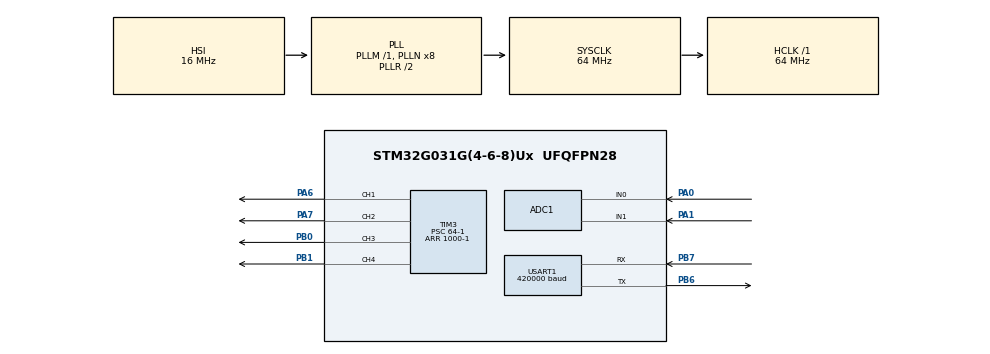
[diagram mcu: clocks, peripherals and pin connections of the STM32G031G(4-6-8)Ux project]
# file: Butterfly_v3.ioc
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ADC1.Channel-1\#ChannelRegularConversion=ADC_CHANNEL_0
ADC1.Channel-2\#ChannelRegularConversion=ADC_CHANNEL_1
ADC1.Channel-3\#ChannelRegularConversion=ADC_CHANNEL_TEMPSENSOR
ADC1.Channel-4\#ChannelRegularConversion=ADC_CHANNEL_VREFINT
ADC1.ContinuousConvMode=ENABLE
ADC1.NbrOfConversion=4
ADC1.NbrOfConversionFlag=1
ADC1.Rank-1\#ChannelRegularConversion=1
ADC1.Rank-2\#ChannelRegularConversion=2
ADC1.Rank-3\#ChannelRegularConversion=3
ADC1.Rank-4\#ChannelRegularConversion=4
ADC1.SamplingTime-1\#ChannelRegularConversion=ADC_SAMPLINGTIME_COMMON_1
ADC1.SamplingTime-2\#ChannelRegularConversion=ADC_SAMPLINGTIME_COMMON_1
ADC1.SamplingTime-3\#ChannelRegularConversion=ADC_SAMPLINGTIME_COMMON_1
ADC1.SamplingTime-4\#ChannelRegularConversion=ADC_SAMPLINGTIME_COMMON_1
ADC1.SamplingTimeCommon1=ADC_SAMPLETIME_160CYCLES_5
ADC1.SelectedChannel=ADC_CHANNEL_0|ADC_CHANNEL_1|ADC_CHANNEL_TEMPSENSOR|ADC_CHANNEL_VREFINT
ADC1.master=1
Dma.ADC1.1.Direction=DMA_PERIPH_TO_MEMORY
Dma.ADC1.1.EventEnable=DISABLE
Dma.ADC1.1.Instance=DMA1_Channel2
Dma.ADC1.1.MemDataAlignment=DMA_MDATAALIGN_HALFWORD
Dma.ADC1.1.MemInc=DMA_MINC_ENABLE
Dma.ADC1.1.Mode=DMA_CIRCULAR
Dma.ADC1.1.PeriphDataAlignment=DMA_PDATAALIGN_HALFWORD
Dma.ADC1.1.PeriphInc=DMA_PINC_DISABLE
Dma.ADC1.1.Polarity=HAL_DMAMUX_REQ_GEN_RISING
Dma.ADC1.1.Priority=DMA_PRIORITY_LOW
Dma.ADC1.1.RequestNumber=1
Dma.ADC1.1.SignalID=NONE
Dma.ADC1.1.SyncEnable=DISABLE
Dma.ADC1.1.SyncPolarity=HAL_DMAMUX_SYNC_NO_EVENT
Dma.ADC1.1.SyncRequestNumber=1
Dma.ADC1.1.SyncSignalID=NONE
Dma.Request0=USART1_RX
Dma.Request1=ADC1
Dma.USART1_RX.0.Direction=DMA_PERIPH_TO_MEMORY
Dma.USART1_RX.0.EventEnable=DISABLE
Dma.USART1_RX.0.Instance=DMA1_Channel1
Dma.USART1_RX.0.MemDataAlignment=DMA_MDATAALIGN_BYTE
Dma.USART1_RX.0.MemInc=DMA_MINC_ENABLE
Dma.USART1_RX.0.Mode=DMA_NORMAL
Dma.USART1_RX.0.PeriphDataAlignment=DMA_PDATAALIGN_BYTE
Dma.USART1_RX.0.PeriphInc=DMA_PINC_DISABLE
Dma.USART1_RX.0.Polarity=HAL_DMAMUX_REQ_GEN_RISING
Dma.USART1_RX.0.Priority=DMA_PRIORITY_LOW
Dma.USART1_RX.0.RequestNumber=1
Dma.USART1_RX.0.SignalID=NONE
Dma.USART1_RX.0.SyncEnable=DISABLE
Dma.USART1_RX.0.SyncPolarity=HAL_DMAMUX_SYNC_NO_EVENT
Dma.USART1_RX.0.SyncRequestNumber=1
Dma.USART1_RX.0.SyncSignalID=NONE
Mcu.Family=STM32G0
Mcu.Name=STM32G031G(4-6-8)Ux
Mcu.Package=UFQFPN28
NVIC.DMA1_Channel1_IRQn=true\:0\:0\:false\:false\:true\:false\:true\:true
NVIC.DMA1_Channel2_3_IRQn=true\:0\:0\:false\:false\:true\:false\:true\:true
NVIC.TIM17_IRQn=true\:3\:0\:false\:false\:true\:false\:true\:true
NVIC.TimeBase=TIM17_IRQn
NVIC.TimeBaseIP=TIM17
PA0.Mode=IN0
PA0.Signal=ADC1_IN0
PA1.Mode=IN1
PA1.Signal=ADC1_IN1
PA13.Mode=Serial_Wire
PA13.Signal=SYS_SWDIO
PA14-BOOT0.Mode=Serial_Wire
PA14-BOOT0.Signal=SYS_SWCLK
PA6.Signal=S_TIM3_CH1
PA7.Signal=S_TIM3_CH2
PB0.Signal=S_TIM3_CH3
PB1.Signal=S_TIM3_CH4
PB6.Mode=Asynchronous
PB6.Signal=USART1_TX
PB7.Mode=Asynchronous
PB7.Signal=USART1_RX
ProjectManager.HeapSize=0x200
ProjectManager.StackSize=0x400
ProjectManager.TargetToolchain=CMake
RCC.ADCFreq_Value=64000000
RCC.AHBFreq_Value=64000000
RCC.CortexFreq_Value=64000000
RCC.EXTERNAL_CLOCK_VALUE=12288000
RCC.HCLKFreq_Value=64000000
RCC.HSE_VALUE=8000000
RCC.HSI_VALUE=16000000
RCC.SYSCLKFreq_VALUE=64000000
RCC.SYSCLKSource=RCC_SYSCLKSOURCE_PLLCLK
RCC.VCOOutputFreq_Value=128000000
SH.S_TIM3_CH1.0=TIM3_CH1,PWM Generation1 CH1
SH.S_TIM3_CH2.0=TIM3_CH2,PWM Generation2 CH2
SH.S_TIM3_CH3.0=TIM3_CH3,PWM Generation3 CH3
SH.S_TIM3_CH4.0=TIM3_CH4,PWM Generation4 CH4
STMicroelectronics.X-CUBE-ALGOBUILD.1.4.0.LibraryCcDSPOoLibraryJjDSPOoLibrary=true
TIM3.Channel-PWM\ Generation1\ CH1=TIM_CHANNEL_1
TIM3.Channel-PWM\ Generation2\ CH2=TIM_CHANNEL_2
TIM3.Channel-PWM\ Generation3\ CH3=TIM_CHANNEL_3
TIM3.Channel-PWM\ Generation4\ CH4=TIM_CHANNEL_4
TIM3.Period=1000-1
TIM3.Prescaler=64-1
USART1.BaudRate=420000
USART1.Parity=PARITY_NONE
USART1.RxPinLevelInvertParam=ADVFEATURE_RXINV_DISABLE
USART1.SwapParam=ADVFEATURE_SWAP_DISABLE
USART1.TxPinLevelInvertParam=ADVFEATURE_TXINV_DISABLE
USART1.VirtualMode-Asynchronous=VM_ASYNC
USART1.WordLength=WORDLENGTH_8B
VP_ADC1_TempSens_Input.Mode=IN-TempSens
VP_ADC1_Vref_Input.Mode=IN-Vrefint
VP_STMicroelectronics.X-CUBE-ALGOBUILD_VS_DSPOoLibraryJjLibrary_1.4.0_1.4.0.Mode=DSPOoLibraryJjLibrary
VP_SYS_VS_tim17.Mode=TIM17
VP_TIM2_VS_ClockSourceINT.Mode=Internal
board=custom

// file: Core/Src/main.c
/* USER CODE BEGIN Header */
/**
  ******************************************************************************
  * @file           : main.c
  * @brief          : Main program body
  ******************************************************************************
  * @attention
  *
  * Copyright (c) 2026 STMicroelectronics.
  * All rights reserved.
  *
  * This software is licensed under terms that can be found in the LICENSE file
  * in the root directory of this software component.
  * If no LICENSE file comes with this software, it is provided AS-IS.
  *
  ******************************************************************************
  */
/* USER CODE END Header */
#include "main.h"
#include "adc.h"
#include "dma.h"
#include "tim.h"
#include "usart.h"
#include "gpio.h"

/* USER CODE BEGIN Includes */
#include "butterfly.h"
/* USER CODE END Includes */

void SystemClock_Config(void);

int main(void)
{

  /* MCU Configuration--------------------------------------------------------*/

  /* Reset of all peripherals, Initializes the Flash interface and the Systick. */
  HAL_Init();

  /* Configure the system clock */
  SystemClock_Config();

  /* USER CODE BEGIN SysInit */
  HAL_Delay(1000);

  /* USER CODE END SysInit */

  /* Initialize all configured peripherals */
  MX_GPIO_Init();
  MX_DMA_Init();
  MX_USART1_UART_Init();
  MX_ADC1_Init();
  MX_TIM2_Init();
  MX_TIM3_Init();
  /* USER CODE BEGIN 2 */

  Butterfly_Init();
  /* USER CODE END 2 */

  /* Infinite loop */
  /* USER CODE BEGIN WHILE */
  while (1)
  {
    Butterfly_Task();
    /* USER CODE END WHILE */

  }
}

void SystemClock_Config(void)
{
  RCC_OscInitTypeDef RCC_OscInitStruct = {0};
  RCC_ClkInitTypeDef RCC_ClkInitStruct = {0};

  /** Configure the main internal regulator output voltage
  */
  HAL_PWREx_ControlVoltageScaling(PWR_REGULATOR_VOLTAGE_SCALE1);

  /** Initializes the RCC Oscillators according to the specified parameters
  * in the RCC_OscInitTypeDef structure.
  */
  RCC_OscInitStruct.OscillatorType = RCC_OSCILLATORTYPE_HSI;
  RCC_OscInitStruct.HSIState = RCC_HSI_ON;
  RCC_OscInitStruct.HSIDiv = RCC_HSI_DIV1;
  RCC_OscInitStruct.HSICalibrationValue = RCC_HSICALIBRATION_DEFAULT;
  RCC_OscInitStruct.PLL.PLLState = RCC_PLL_ON;
  RCC_OscInitStruct.PLL.PLLSource = RCC_PLLSOURCE_HSI;
  RCC_OscInitStruct.PLL.PLLM = RCC_PLLM_DIV1;
  RCC_OscInitStruct.PLL.PLLN = 8;
  RCC_OscInitStruct.PLL.PLLP = RCC_PLLP_DIV2;
  RCC_OscInitStruct.PLL.PLLQ = RCC_PLLQ_DIV2;
  RCC_OscInitStruct.PLL.PLLR = RCC_PLLR_DIV2;
  if (HAL_RCC_OscConfig(&RCC_OscInitStruct) != HAL_OK)
  {
    Error_Handler();
  }

  /** Initializes the CPU, AHB and APB buses clocks
  */
  RCC_ClkInitStruct.ClockType = RCC_CLOCKTYPE_HCLK|RCC_CLOCKTYPE_SYSCLK
                              |RCC_CLOCKTYPE_PCLK1;
  RCC_ClkInitStruct.SYSCLKSource = RCC_SYSCLKSOURCE_PLLCLK;
  RCC_ClkInitStruct.AHBCLKDivider = RCC_SYSCLK_DIV1;
  RCC_ClkInitStruct.APB1CLKDivider = RCC_HCLK_DIV1;

  if (HAL_RCC_ClockConfig(&RCC_ClkInitStruct, FLASH_LATENCY_2) != HAL_OK)
  {
    Error_Handler();
  }
}

void HAL_TIM_PeriodElapsedCallback(TIM_HandleTypeDef *htim)
{
  if (htim->Instance == TIM17)
  {
    HAL_IncTick();
  }
}

void Error_Handler(void)
{
  __disable_irq();
  while (1)
  {
  }
}
